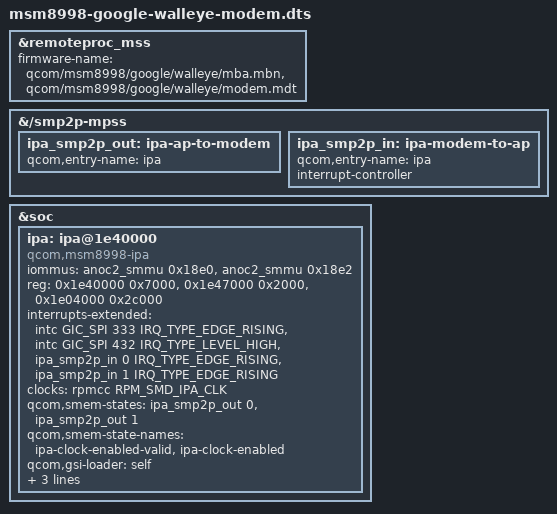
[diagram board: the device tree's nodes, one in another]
// SPDX-License-Identifier: GPL-2.0-only
/*
 * Variant modem of the walleye board file (item walleye-modem-mss-dtb; research walleye-modem-way, walleye-modem-blobs-found): the same tree plus the modem
 * subsystem (remoteproc_mss) on the phone's own firmware set. The main file stays as it is: the images already tried keep their dtb byte for byte.
 *
 * The carve-outs are the main file's, which are the phone's running ones (mpss_mem 0x8cc00000/120 MiB, mba_mem 0x94500000/2 MiB: tests/fixtures/phone-text/walleye-running-fdt-memory.cap,
 * modem_region and pil_mba_region); the metadata block (mdata_mem) and the rmtfs block (rmtfs_mem, 0x88f00000, client 1, vmid MSS_MSA) are mainline's msm8998.dtsi as it stands:
 * the phone's running fdt (the fixture: reserved regions with a reg) holds no rmtfs region, so where the modem may put its remote file system on this phone is not known yet (decision 2026-11-27-walleye-modem-rmtfs-region-not-known-yet).
 * The firmware names are the files of the phone's own modem_b partition (/image: mba.mbn, modem.mdt, b00-b27), which the ramdisk of the image holds under /lib/firmware
 * from ~/lab-material (never git). The node is enabled the way mainline's msm8998-mtp.dts does: status only, no supplies.
 */
#include "msm8998-google-walleye.dts"

&remoteproc_mss {
	firmware-name = "qcom/msm8998/google/walleye/mba.mbn",
			"qcom/msm8998/google/walleye/modem.mdt";

	status = "okay";
};

/*
 * The modem's net port (item walleye-modem-net-port-ipa-node; decision 2026-11-27-walleye-net-port-from-mainline-ipa): ModemManager lists a QMI modem only with a net port, and on this SoC that is the IPA's.
 * Every value is cited in tests/fixtures/kernel-text/msm8998-ipa-sources.txt and judged by tests/host/dtb-modem-ipa.sh: the smp2p entries, ipa-reg and ipa-shared of the msm8998-mainline fork (block B), the gsi range,
 * the two interrupts and the two SMMU stream ids (0x18e0 ap, 0x18e2 uc) of Google's wahoo dtsi (blocks A, A3). The AP loads the IPA firmware (the wahoo dtsi has it through Trust Zone, pas-id 0xF; the OnePlus 5's node
 * does too, block B2): the phone's own ipa_fws.mdt, in the phone's ipa/gpu block (ipa_gpu_mem), the firmware set the ramdisk is given from ~/lab-material, never git.
 * No `interconnects`: v7.3 has no msm8998 interconnect provider, so of_icc_bulk_get gets NULL paths and the driver runs unvoted; the binding requires the property, so dtbs_check says so (research
 * walleye-modem-net-port-how-it-stands, "what is left"). NOT KNOWN YET: that the driver probes on this phone (the OnePlus 5 keeps it off autoload for stability); that the GSI firmware authenticates in 0x95b00000.
 */
&{/smp2p-mpss} {
	ipa_smp2p_out: ipa-ap-to-modem {
		qcom,entry-name = "ipa";
		#qcom,smem-state-cells = <1>;
	};

	ipa_smp2p_in: ipa-modem-to-ap {
		qcom,entry-name = "ipa";
		interrupt-controller;
		#interrupt-cells = <2>;
	};
};

&soc {
	ipa: ipa@1e40000 {
		compatible = "qcom,msm8998-ipa";

		iommus = <&anoc2_smmu 0x18e0>,
			 <&anoc2_smmu 0x18e2>;
		reg = <0x1e40000 0x7000>,
		      <0x1e47000 0x2000>,
		      <0x1e04000 0x2c000>;
		reg-names = "ipa-reg",
			    "ipa-shared",
			    "gsi";

		interrupts-extended = <&intc GIC_SPI 333 IRQ_TYPE_EDGE_RISING>,
				      <&intc GIC_SPI 432 IRQ_TYPE_LEVEL_HIGH>,
				      <&ipa_smp2p_in 0 IRQ_TYPE_EDGE_RISING>,
				      <&ipa_smp2p_in 1 IRQ_TYPE_EDGE_RISING>;
		interrupt-names = "ipa",
				  "gsi",
				  "ipa-clock-query",
				  "ipa-setup-ready";

		clocks = <&rpmcc RPM_SMD_IPA_CLK>;
		clock-names = "core";

		qcom,smem-states = <&ipa_smp2p_out 0>,
				   <&ipa_smp2p_out 1>;
		qcom,smem-state-names = "ipa-clock-enabled-valid",
					"ipa-clock-enabled";

		qcom,gsi-loader = "self";
		memory-region = <&ipa_gpu_mem>;
		firmware-name = "qcom/msm8998/google/walleye/ipa_fws.mdt";

		status = "okay";
	};
};
